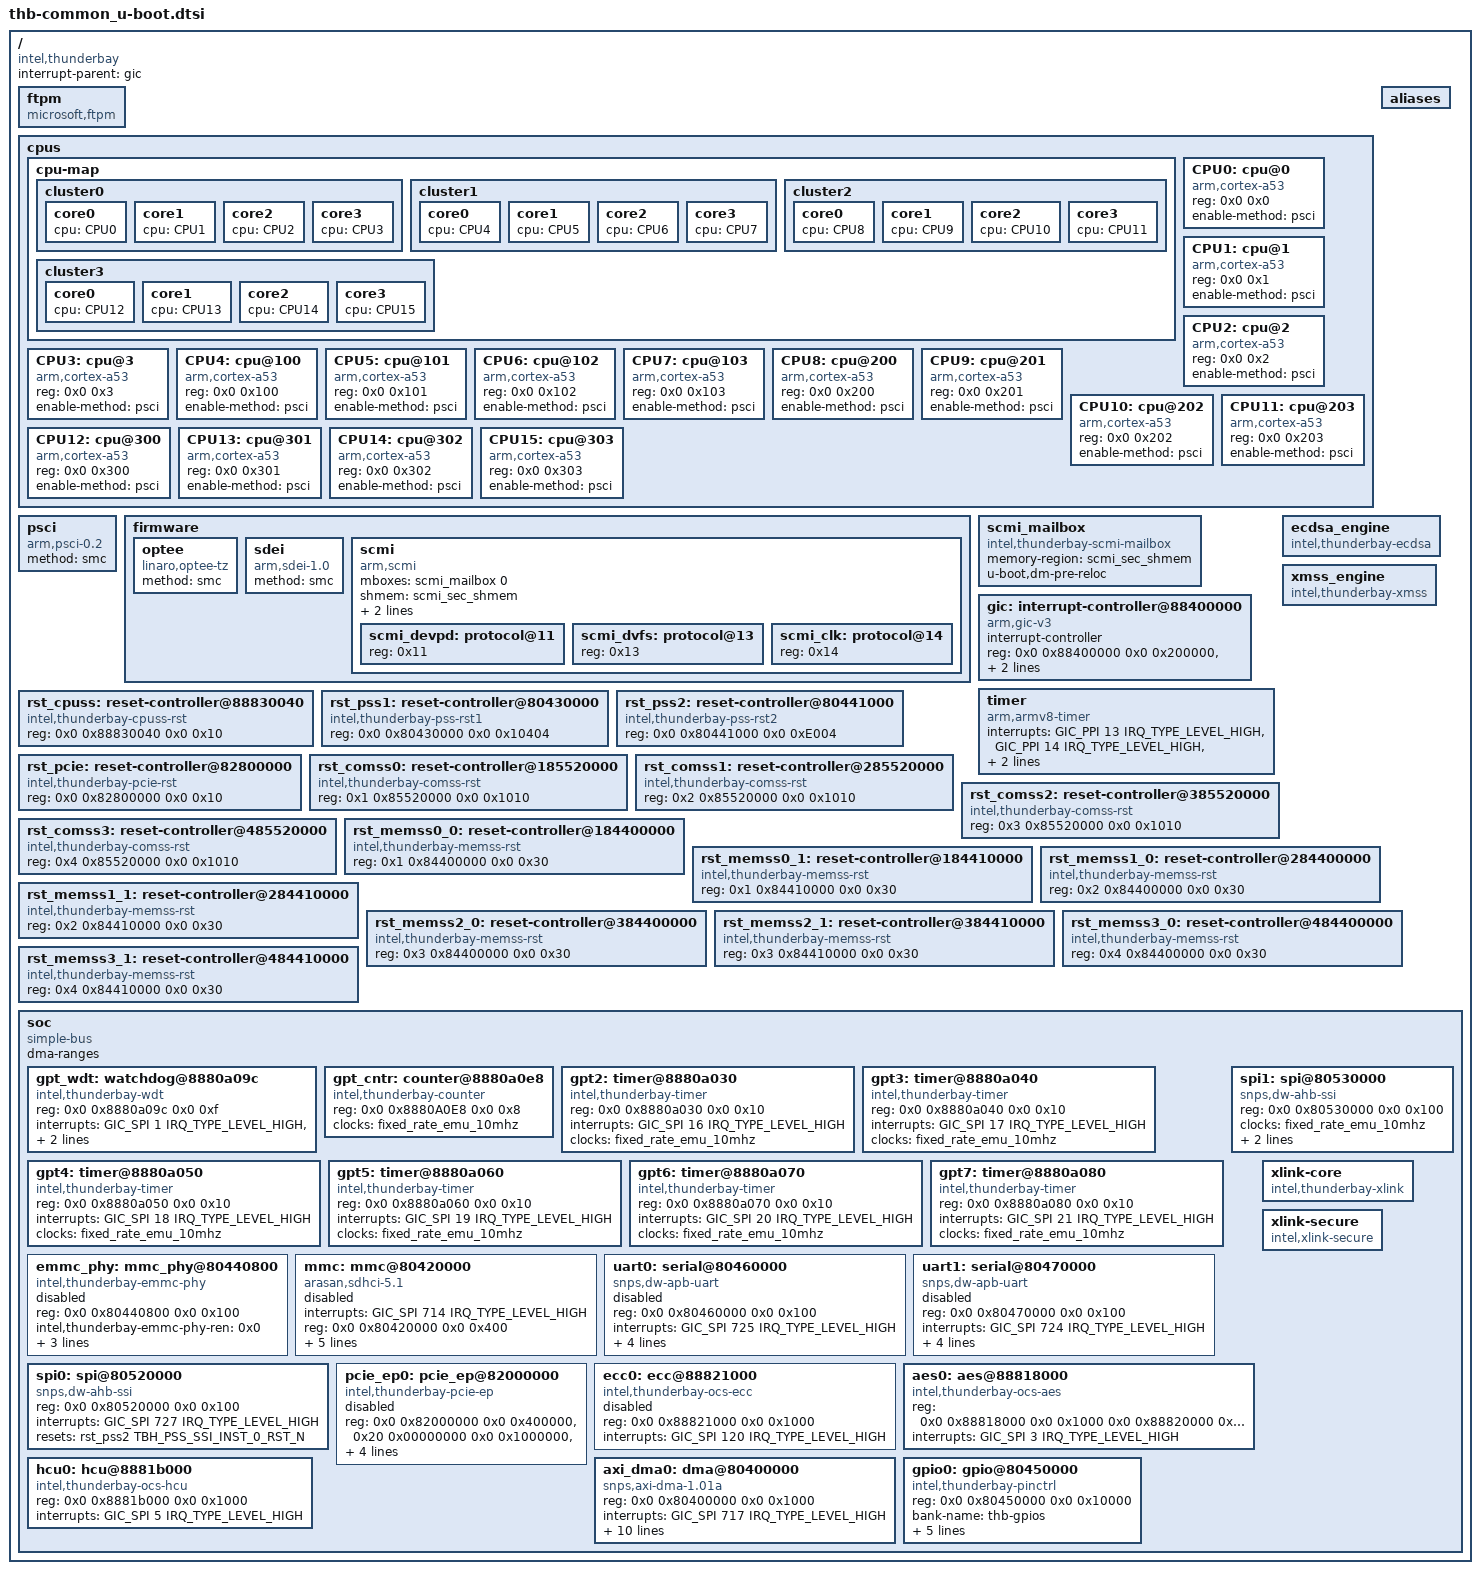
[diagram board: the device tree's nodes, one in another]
/*
 * Device tree describing features common across Thunder Bay SoCs
 *
 * Copyright (c) 2020 Intel Corporation.
 *
 * SPDX-License-Identifier: GPL-2.0
 *
 */

/dts-v1/;

#include <dt-bindings/clock/thunderbay-clocks.h>
#include <dt-bindings/interrupt-controller/arm-gic.h>
#include <dt-bindings/reset/thunderbay-reset.h>


/ {
	compatible = "intel,thunderbay";
	interrupt-parent = <&gic>;

	ftpm {
		compatible = "microsoft,ftpm";
	};

	cpus {
		#address-cells = <2>;
		#size-cells = <0>;

		cpu-map {
			cluster0 {
				core0 {
					cpu = <&CPU0>;
				};
				core1 {
					cpu = <&CPU1>;
				};
				core2 {
					cpu = <&CPU2>;
				};
				core3 {
					cpu = <&CPU3>;
				};
			};
			cluster1 {
				core0 {
					cpu = <&CPU4>;
				};
				core1 {
					cpu = <&CPU5>;
				};
				core2 {
					cpu = <&CPU6>;
				};
				core3 {
					cpu = <&CPU7>;
				};
			};
			cluster2 {
				core0 {
					cpu = <&CPU8>;
				};
				core1 {
					cpu = <&CPU9>;
				};
				core2 {
					cpu = <&CPU10>;
				};
				core3 {
					cpu = <&CPU11>;
				};
			};
			cluster3 {
				core0 {
					cpu = <&CPU12>;
				};
				core1 {
					cpu = <&CPU13>;
				};
				core2 {
					cpu = <&CPU14>;
				};
				core3 {
					cpu = <&CPU15>;
				};
			};
		};

		CPU0: cpu@0 {
			compatible = "arm,cortex-a53";
			device_type = "cpu";
			reg = <0x0 0x0>;
			enable-method = "psci";
		};

		CPU1: cpu@1 {
			compatible = "arm,cortex-a53";
			device_type = "cpu";
			reg = <0x0 0x1>;
			enable-method = "psci";
		};

		CPU2: cpu@2 {
			compatible = "arm,cortex-a53";
			device_type = "cpu";
			reg = <0x0 0x2>;
			enable-method = "psci";
		};

		CPU3: cpu@3 {
			compatible = "arm,cortex-a53";
			device_type = "cpu";
			reg = <0x0 0x3>;
			enable-method = "psci";
		};

		CPU4: cpu@100 {
			compatible = "arm,cortex-a53";
			device_type = "cpu";
			reg = <0x0 0x100>;
			enable-method = "psci";
		};

		CPU5: cpu@101 {
			compatible = "arm,cortex-a53";
			device_type = "cpu";
			reg = <0x0 0x101>;
			enable-method = "psci";
		};

		CPU6: cpu@102 {
			compatible = "arm,cortex-a53";
			device_type = "cpu";
			reg = <0x0 0x102>;
			enable-method = "psci";
		};

		CPU7: cpu@103 {
			compatible = "arm,cortex-a53";
			device_type = "cpu";
			reg = <0x0 0x103>;
			enable-method = "psci";
		};

		CPU8: cpu@200 {
			compatible = "arm,cortex-a53";
			device_type = "cpu";
			reg = <0x0 0x200>;
			enable-method = "psci";
		};

		CPU9: cpu@201 {
			compatible = "arm,cortex-a53";
			device_type = "cpu";
			reg = <0x0 0x201>;
			enable-method = "psci";
		};

		CPU10: cpu@202 {
			compatible = "arm,cortex-a53";
			device_type = "cpu";
			reg = <0x0 0x202>;
			enable-method = "psci";
		};

		CPU11: cpu@203 {
			compatible = "arm,cortex-a53";
			device_type = "cpu";
			reg = <0x0 0x203>;
			enable-method = "psci";
		};

		CPU12: cpu@300 {
			compatible = "arm,cortex-a53";
			device_type = "cpu";
			reg = <0x0 0x300>;
			enable-method = "psci";
		};

		CPU13: cpu@301 {
			compatible = "arm,cortex-a53";
			device_type = "cpu";
			reg = <0x0 0x301>;
			enable-method = "psci";
		};

		CPU14: cpu@302 {
			compatible = "arm,cortex-a53";
			device_type = "cpu";
			reg = <0x0 0x302>;
			enable-method = "psci";
		};

		CPU15: cpu@303 {
			compatible = "arm,cortex-a53";
			device_type = "cpu";
			reg = <0x0 0x303>;
			enable-method = "psci";
		};
	};

	psci {
		compatible = "arm,psci-0.2";
		method = "smc";
	};

	firmware {
		optee {
			compatible = "linaro,optee-tz";
			method = "smc";
		};
		sdei {
			compatible = "arm,sdei-1.0";
			method = "smc";
		};

		scmi: scmi {
			compatible = "arm,scmi";
			mboxes = <&scmi_mailbox 0>;
			shmem = <&scmi_sec_shmem>;
			mbox-names = "tx";
			#address-cells = <1>;
			#size-cells = <0>;
			u-boot,dm-pre-reloc;

			scmi_devpd: protocol@11 {
				reg = <0x11>;
				#power-domain-cells = <1>;
			};

			scmi_dvfs: protocol@13 {
				reg = <0x13>;
				#clock-cells = <1>;
			};

			scmi_clk: protocol@14 {
				reg = <0x14>;
				#clock-cells = <1>;
			};
		};

	};

	scmi_mailbox: scmi_mailbox {
		compatible = "intel,thunderbay-scmi-mailbox";
		#mbox-cells = <1>;
		memory-region = <&scmi_sec_shmem>;
		u-boot,dm-pre-reloc;
	};

	aliases {
	};

	gic: interrupt-controller@88400000 {
		compatible = "arm,gic-v3";
		interrupt-controller;
		#interrupt-cells = <3>;
		reg = <0x0 0x88400000 0x0 0x200000>,	/* GICD */
		      <0x0 0x88600000 0x0 0x200000>;	/* GICR */
		/* VGIC maintenance interrupt */
		interrupts = <GIC_PPI 9 IRQ_TYPE_LEVEL_HIGH>;
	};

	timer {
		compatible = "arm,armv8-timer";
		/* Secure, non-secure, virtual, and hypervisor */
		interrupts = <GIC_PPI 13 IRQ_TYPE_LEVEL_HIGH>,
		             <GIC_PPI 14 IRQ_TYPE_LEVEL_HIGH>,
		             <GIC_PPI 11 IRQ_TYPE_LEVEL_HIGH>,
		             <GIC_PPI 10 IRQ_TYPE_LEVEL_HIGH>;
	};

	ecdsa_engine: ecdsa_engine {
		compatible = "intel,thunderbay-ecdsa";
	};

	xmss_engine: xmss_engine {
		compatible = "intel,thunderbay-xmss";
	};

	rst_cpuss: reset-controller@88830040 {
		compatible = "intel,thunderbay-cpuss-rst";
		reg = <0x0 0x88830040 0x0 0x10>;
		#reset-cells = <1>;
	};

	rst_pss1: reset-controller@80430000 {
		compatible = "intel,thunderbay-pss-rst1";
		reg = <0x0 0x80430000 0x0 0x10404>;
		#reset-cells = <1>;
	};

	rst_pss2: reset-controller@80441000 {
		compatible = "intel,thunderbay-pss-rst2";
		reg = <0x0 0x80441000 0x0 0xE004>;
		#reset-cells = <1>;
	};

	rst_pcie: reset-controller@82800000 {
		compatible = "intel,thunderbay-pcie-rst";
		reg = <0x0 0x82800000 0x0 0x10>;
		#reset-cells = <1>;
	};

	rst_comss0: reset-controller@185520000 {
		compatible = "intel,thunderbay-comss-rst";
		reg = <0x1 0x85520000 0x0 0x1010>;
		#reset-cells = <1>;
	};

	rst_comss1: reset-controller@285520000 {
		compatible = "intel,thunderbay-comss-rst";
		reg = <0x2 0x85520000 0x0 0x1010>;
		#reset-cells = <1>;
	};

	rst_comss2: reset-controller@385520000 {
		compatible = "intel,thunderbay-comss-rst";
		reg = <0x3 0x85520000 0x0 0x1010>;
		#reset-cells = <1>;
	};

	rst_comss3: reset-controller@485520000 {
		compatible = "intel,thunderbay-comss-rst";
		reg = <0x4 0x85520000 0x0 0x1010>;
		#reset-cells = <1>;
	};

	rst_memss0_0: reset-controller@184400000 {
		compatible = "intel,thunderbay-memss-rst";
		reg = <0x1 0x84400000 0x0 0x30>;
		#reset-cells = <1>;
	};

	rst_memss0_1: reset-controller@184410000 {
		compatible = "intel,thunderbay-memss-rst";
		reg = <0x1 0x84410000 0x0 0x30>;
		#reset-cells = <1>;
	};

	rst_memss1_0: reset-controller@284400000 {
		compatible = "intel,thunderbay-memss-rst";
		reg = <0x2 0x84400000 0x0 0x30>;
		#reset-cells = <1>;
	};

	rst_memss1_1: reset-controller@284410000 {
		compatible = "intel,thunderbay-memss-rst";
		reg = <0x2 0x84410000 0x0 0x30>;
		#reset-cells = <1>;
	};

	rst_memss2_0: reset-controller@384400000 {
		compatible = "intel,thunderbay-memss-rst";
		reg = <0x3 0x84400000 0x0 0x30>;
		#reset-cells = <1>;
	};

	rst_memss2_1: reset-controller@384410000 {
		compatible = "intel,thunderbay-memss-rst";
		reg = <0x3 0x84410000 0x0 0x30>;
		#reset-cells = <1>;
	};

	rst_memss3_0: reset-controller@484400000 {
		compatible = "intel,thunderbay-memss-rst";
		reg = <0x4 0x84400000 0x0 0x30>;
		#reset-cells = <1>;
	};

	rst_memss3_1: reset-controller@484410000 {
		compatible = "intel,thunderbay-memss-rst";
		reg = <0x4 0x84410000 0x0 0x30>;
		#reset-cells = <1>;
	};

	soc {
		compatible = "simple-bus";
		#address-cells = <2>;
		#size-cells = <2>;
		ranges;
		dma-ranges;

		gpt_wdt: watchdog@8880a09c {
			compatible = "intel,thunderbay-wdt";
			reg = <0x0 0x8880a09c 0x0 0xf>;
			interrupts = <GIC_SPI 1 IRQ_TYPE_LEVEL_HIGH>,
			             <GIC_SPI 2 IRQ_TYPE_LEVEL_HIGH>;
			interrupt-names = "threshold","timeout";
			clocks = <&fixed_rate_emu_10mhz>;
/*			clocks = <&scmi_clk TIMER_WDT_XTAL_CLK>; */
			status = "okay";
		};

		gpt_cntr: counter@8880a0e8 {
			compatible = "intel,thunderbay-counter";
			reg = <0x0 0x8880A0E8 0x0 0x8>;
			clocks = <&fixed_rate_emu_10mhz>;
/*			clocks = <&scmi_clk TIMER_CLK>; */
			status = "okay";
		};

		gpt2: timer@8880a030 {
			compatible = "intel,thunderbay-timer";
			reg = <0x0 0x8880a030 0x0 0x10>;
			interrupts = <GIC_SPI 16 IRQ_TYPE_LEVEL_HIGH>;
			clocks = <&fixed_rate_emu_10mhz>;
/*			clocks = <&scmi_clk TIMER_CLK>; */
			status = "okay";
		};

		gpt3: timer@8880a040 {
			compatible = "intel,thunderbay-timer";
			reg = <0x0 0x8880a040 0x0 0x10>;
			interrupts = <GIC_SPI 17 IRQ_TYPE_LEVEL_HIGH>;
			clocks = <&fixed_rate_emu_10mhz>;
/*			clocks = <&scmi_clk TIMER_CLK>; */
			status = "okay";
		};

		gpt4: timer@8880a050 {
			compatible = "intel,thunderbay-timer";
			reg = <0x0 0x8880a050 0x0 0x10>;
			interrupts = <GIC_SPI 18 IRQ_TYPE_LEVEL_HIGH>;
			clocks = <&fixed_rate_emu_10mhz>;
/*			clocks = <&scmi_clk TIMER_CLK>; */
			status = "okay";
		};

		gpt5: timer@8880a060 {
			compatible = "intel,thunderbay-timer";
			reg = <0x0 0x8880a060 0x0 0x10>;
			interrupts = <GIC_SPI 19 IRQ_TYPE_LEVEL_HIGH>;
			clocks = <&fixed_rate_emu_10mhz>;
/*			clocks = <&scmi_clk TIMER_CLK>; */
			status = "okay";
		};

		gpt6: timer@8880a070 {
			compatible = "intel,thunderbay-timer";
			reg = <0x0 0x8880a070 0x0 0x10>;
			interrupts = <GIC_SPI 20 IRQ_TYPE_LEVEL_HIGH>;
			clocks = <&fixed_rate_emu_10mhz>;
/*			clocks = <&scmi_clk TIMER_CLK>; */
			status = "okay";
		};

		gpt7: timer@8880a080 {
			compatible = "intel,thunderbay-timer";
			reg = <0x0 0x8880a080 0x0 0x10>;
			interrupts = <GIC_SPI 21 IRQ_TYPE_LEVEL_HIGH>;
			clocks = <&fixed_rate_emu_10mhz>;
/*			clocks = <&scmi_clk TIMER_CLK>; */
			status = "okay";
		};

		emmc_phy: mmc_phy@80440800 {
			#phy-cells = <0>;
			compatible = "intel,thunderbay-emmc-phy";
			status = "disabled";
			reg = <0x0 0x80440800 0x0 0x100>;
			clock-names = "emmcclk";
			intel,thunderbay-emmc-phy-ren = <0x0>;
			intel,thunderbay-emmc-phy-otap-dly = <0x26>;
			intel,thunderbay-emmc-phy-itap-dly = <0x0>;
			intel,thunderbay-emmc-phy-sel-strb = <0x5>;
		};

		mmc: mmc@80420000 {
			compatible = "arasan,sdhci-5.1";
			status = "disabled";
			interrupts = <GIC_SPI 714 IRQ_TYPE_LEVEL_HIGH>;
			reg = <0x0 0x80420000 0x0 0x400>;
			clock-names = "clk_xin", "clk_ahb";
			phys = <&emmc_phy>;
			phy-names = "phy_arasan";
			clock-output-names = "emmc_cardclock";
			resets = <&rst_pss1 TBH_PSS_EMMC_RST_N>;
			#clock-cells = <0x0>;
			sd-uhs-sdr25;
			bus-width = <0x4>;
		};

		uart0: serial@80460000 {
			compatible = "snps,dw-apb-uart";
			reg = <0x0 0x80460000 0x0 0x100>;
			interrupts = <GIC_SPI 725 IRQ_TYPE_LEVEL_HIGH>;
			clock-frequency = <50000000>;
/*			clocks = <&scmi_clk UART_0_SCLK>,
			         <&scmi_clk UART_0_CLK>;
			clock-names = "baudclk", "apb_pclk"; */
			resets = <&rst_pss1 TBH_PSS_UART_INST_0_RST_N>;
			reg-shift = <2>;
			reg-io-width = <4>;
			status = "disabled";
		};

		uart1: serial@80470000 {
			compatible = "snps,dw-apb-uart";
			reg = <0x0 0x80470000 0x0 0x100>;
			interrupts = <GIC_SPI 724 IRQ_TYPE_LEVEL_HIGH>;
			clock-frequency = <10000000>;
/*			clocks = <&scmi_clk UART_1_SCLK>,
			         <&scmi_clk UART_1_CLK>;
			clock-names = "baudclk", "apb_pclk"; */
			resets = <&rst_pss1 TBH_PSS_UART_INST_1_RST_N>;
			reg-shift = <2>;
			reg-io-width = <4>;
			status = "disabled";
		};

		spi0: spi@80520000 {
			compatible = "snps,dw-ahb-ssi";
			reg = <0x0 0x80520000 0x0 0x100>;
			interrupts = <GIC_SPI 727 IRQ_TYPE_LEVEL_HIGH>;
			resets = <&rst_pss2 TBH_PSS_SSI_INST_0_RST_N>;
			#address-cells = <1>;
			#size-cells = <0>;
			status = "okay";
		};

		spi1: spi@80530000 {
			compatible = "snps,dw-ahb-ssi";
			reg = <0x0 0x80530000 0x0 0x100>;
			clocks = <&fixed_rate_emu_10mhz>;
			interrupts = <GIC_SPI 726 IRQ_TYPE_LEVEL_HIGH>;
			resets = <&rst_pss2 TBH_PSS_SSI_INST_1_RST_N>;
			#address-cells = <1>;
			#size-cells = <0>;
			status = "okay";
		};

		/* EP node */
		pcie_ep0: pcie_ep@82000000 {
			compatible = "intel,thunderbay-pcie-ep", "snps,dw-pcie-ep";
			reg = <0x0 0x82000000 0x0 0x400000>,
				<0x20 0x00000000 0x0 0x1000000>,
				<0x0 0x828b0000 0x0 0x800000>;
			reg-names = "dbi", "addr_space", "apb";
			num-lanes = <2>;
			num-ib-windows = <2>;
			num-ob-windows = <2>;
			status = "disabled";
		};

		ecc0: ecc@88821000 {
                        compatible = "intel,thunderbay-ocs-ecc";
                        reg = <0x0 0x88821000 0x0 0x1000>;
                        interrupts = <GIC_SPI 120 IRQ_TYPE_LEVEL_HIGH>;
                        status = "disabled";
                };

                aes0: aes@88818000 {
                        compatible = "intel,thunderbay-ocs-aes";
                        reg = <0x0 0x88818000 0x0 0x1000
                               0x0 0x88820000 0x0 0x8>;
                        reg-names = "ocs_base", "ocs_wrapper_base";
                        interrupts = <GIC_SPI 3 IRQ_TYPE_LEVEL_HIGH>;
                        status = "okay";
                };

                hcu0: hcu@8881b000 {
                        compatible = "intel,thunderbay-ocs-hcu";
                        reg = <0x0 0x8881b000 0x0 0x1000>;
                        interrupts = <GIC_SPI 5 IRQ_TYPE_LEVEL_HIGH>;
                        status = "okay";
                };

		axi_dma0: dma@80400000 {
			compatible = "snps,axi-dma-1.01a";
			reg = <0x0 0x80400000 0x0 0x1000>;
			reg-names = "axidma_ctrl_regs";
			interrupts = <GIC_SPI 717 IRQ_TYPE_LEVEL_HIGH>;
			clock-names = "core-clk", "cfgr-clk";
			clocks = <&fixed_rate_emu_10mhz>, <&fixed_rate_emu_10mhz>;
			resets = <&rst_pss2 TBH_PSS_DMAC_INST_0_RST_N>;
			#dma-cells = <1>;
			dma-channels = <12>;
			snps,dma-masters = <1>;
			snps,data-width = <4>;
			snps,priority = <0 0 0 0 0 0 0 0 0 0 0 0>;
			snps,block-size = <4096 4096 4096 4096 4096 4096 4096 4096 4096 4096 4096 4096>;
			snps,axi-max-burst-len = <32>;
			status = "okay";
		};

		gpio0: gpio@80450000 {
			compatible = "intel,thunderbay-pinctrl";
			reg = <0x0 0x80450000 0x0 0x10000>;
			bank-name = "thb-gpios";
			gpio-controller;
			#gpio-cells = <2>;
			status = "okay";
			resets = <&rst_pss1 TBH_PSS_GPIO_RST_N>;
			interrupts = <GIC_SPI 705 IRQ_TYPE_LEVEL_HIGH>,
			             <GIC_SPI 704 IRQ_TYPE_LEVEL_HIGH>;
			interrupt-controller;
			#interrupt-cells = <2>;
		};

		xlink-core {
			compatible = "intel,thunderbay-xlink";
		};

		xlink-secure {
			compatible = "intel,xlink-secure";
		};
	};
};

